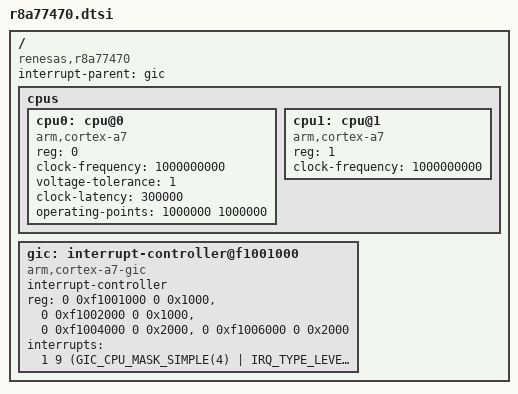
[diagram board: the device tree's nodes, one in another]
/*
 * Device Tree Source for the r8a77470 SoC
 *
 * Copyright (C) 2013-2015 Renesas Electronics Corporation
 *
 * This file is licensed under the terms of the GNU General Public License
 * version 2.  This program is licensed "as is" without any warranty of any
 * kind, whether express or implied.
 */

#include <dt-bindings/interrupt-controller/arm-gic.h>
#include <dt-bindings/interrupt-controller/irq.h>

/ {
	compatible = "renesas,r8a77470";
	interrupt-parent = <&gic>;
	#address-cells = <2>;
	#size-cells = <2>;

	cpus {
		#address-cells = <1>;
		#size-cells = <0>;

		cpu0: cpu@0 {
			device_type = "cpu";
			compatible = "arm,cortex-a7";
			reg = <0>;
			clock-frequency = <1000000000>;
			voltage-tolerance = <1>; /* 1% */
			clock-latency = <300000>; /* 300 us */

			/* kHz - uV - OPPs unknown yet */
			operating-points = <1000000 1000000>;
		};

		cpu1: cpu@1 {
			device_type = "cpu";
			compatible = "arm,cortex-a7";
			reg = <1>;
			clock-frequency = <1000000000>;
		};
	};

	gic: interrupt-controller@f1001000 {
		compatible = "arm,cortex-a7-gic";
		#interrupt-cells = <3>;
		#address-cells = <0>;
		interrupt-controller;
		reg = <0 0xf1001000 0 0x1000>,
			<0 0xf1002000 0 0x1000>,
			<0 0xf1004000 0 0x2000>,
			<0 0xf1006000 0 0x2000>;
		interrupts = <1 9 (GIC_CPU_MASK_SIMPLE(4) | IRQ_TYPE_LEVEL_HIGH)>;
	};
};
